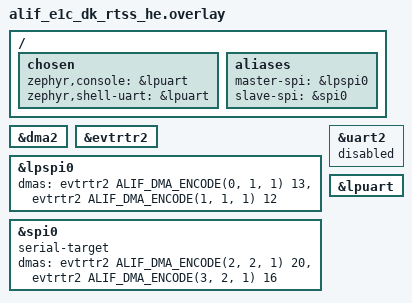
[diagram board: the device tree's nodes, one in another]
/* Copyright (C) 2025 Alif Semiconductor - All Rights Reserved.
 * Use, distribution and modification of this code is permitted under the
 * terms stated in the Alif Semiconductor Software License Agreement
 *
 * You should have received a copy of the Alif Semiconductor Software
 * License Agreement with this file. If not, please write to:
 * contact@alifsemi.com, or visit: https://alifsemi.com/license
 *
 */

/* setting LPSPI0 as master and SPI0 instance as slave.
*
*/

/* For SPI master SS(slave select) as:
 * - H/W controlled (default):
 *   - use SS pinmux as H/W
 *     - example for SPI1 as master "PIN_P14_7__SPI1_SS0_C"
 *  "OR"
 * - S/W controlled using gpio:
 *   - use SS pinmux as gpio
 *     - example for SPI1 as master "PIN_P14_7__GPIO"
 *   - define cs-gpios property
 *     - example for SPI1 as master
 *        cs-gpios = <&gpio14 7 GPIO_ACTIVE_LOW>;
 */

 /* default SPI master SS(slave select) is H/W controlled,
  * enable this to use as S/W controlled using gpio.
  */
#define SPI_MASTER_SS_SW_CONTROLLED_GPIO   0


/ {

	chosen {
		zephyr,console = &lpuart;
		zephyr,shell-uart = &lpuart;
	};
	aliases {
		master-spi = &lpspi0;
		slave-spi = &spi0;
	};
};

&dma2 {
	status = "okay";
};

#include <zephyr/dt-bindings/dma/alif_dma_event_router.h>

&evtrtr2 {
	status = "okay";
};

&lpspi0 {
	status = "okay";
	/*
	 * Cell 0: ALIF_DMA_ENCODE(channel, dma_group, handshake)
	 *   - channel: Physical DMA channel (0 for TX, 1 for RX)
	 *   - dma_group: Input source selection (2) - selects which peripheral input
	 *   - handshake: Enable hardware handshaking (1 for SPI)
	 * Cell 1: Peripheral request number (13 for TX, 12 for RX)
	 */
	dmas = <&evtrtr2 ALIF_DMA_ENCODE(0, 1, 1) 13>,
	       <&evtrtr2 ALIF_DMA_ENCODE(1, 1, 1) 12>;
	dma-names = "txdma", "rxdma";

#if SPI_MASTER_SS_SW_CONTROLLED_GPIO
	cs-gpios = <&gpio2 0 GPIO_ACTIVE_LOW>;
	/* as we are testing Loopback on the same board,
	 * make sure master interrupt priority is
	 * higher than slave interrupt priority.
	 */
	interrupts = <46 0>;
#endif /* SPI_MASTER_SS_SW_CONTROLLED_GPIO */
};

&spi0 {
	status = "okay";
	serial-target;
	/*
	 * Cell 0: ALIF_DMA_ENCODE(channel, dma_group, handshake)
	 *   - channel: Physical DMA channel (2 for TX, 3 for RX)
	 *   - dma_group: Input source selection (2) - selects which peripheral input
	 *   - handshake: Enable hardware handshaking (1 for SPI)
	 * Cell 1: Peripheral request number (20 for TX, 16 for RX)
	 */
	dmas = <&evtrtr2 ALIF_DMA_ENCODE(2, 2, 1) 20>,
	       <&evtrtr2 ALIF_DMA_ENCODE(3, 2, 1) 16>;
	dma-names = "txdma", "rxdma";

#if SPI_MASTER_SS_SW_CONTROLLED_GPIO
	interrupts = <137 1>;
#endif
};

#if SPI_MASTER_SS_SW_CONTROLLED_GPIO
/* use SPI master SS pinmux as gpio. */
&pinctrl_lpspi0 {
	group0 {
		pinmux = < PIN_P1_3__LPSPI_MISO_A >,
			 < PIN_P1_4__LPSPI_MOSI_A >,
			 < PIN_P1_5__LPSPI_SCLK_A >,
			 < PIN_P2_0__GPIO >;
		read-enable = < 0x1 >;
	};
};

&gpio2 {
	status = "okay";
};
#endif /* SPI_MASTER_SS_SW_CONTROLLED_GPIO */

&uart2 {
	status = "disabled";
};

&lpuart {
	status = "okay";
};
